# f2838x_cm_cm_nmi_intrupt_regs register map
Vendor: Texas Instruments
Peripheral module from a debugger description file (folder C2000).
Address unit: 16 bits
Registers are 32-bit, read-write, no defined reset value unless marked. A register's access mark holds for its fields unless they carry their own. Offsets are as the file gives them; lines under a group give offsets from that group; [hi:lo] are bit positions; {n}, {i} and the like mark numbered series; 'fields as' and 'values as' point back to an identical list; <NAME> marks a mode.

## CM_NMI_INTRUPT_REGS — CM NMI INTRUPT Registers
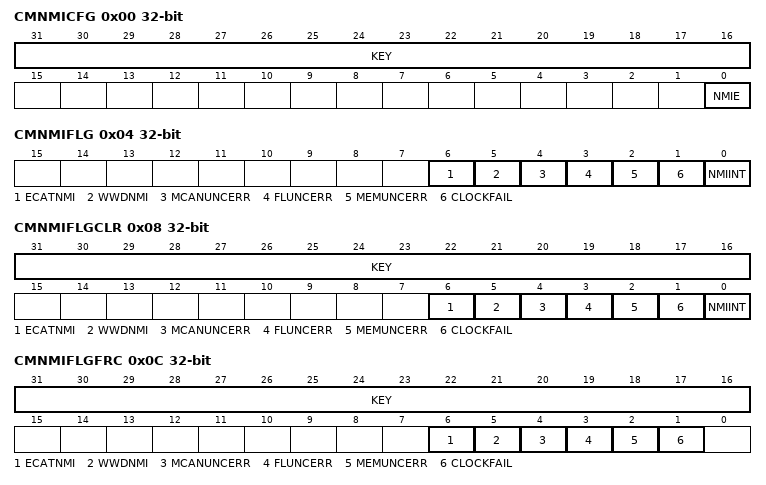
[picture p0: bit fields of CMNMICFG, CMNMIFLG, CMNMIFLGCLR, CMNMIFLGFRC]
0x00 CMNMICFG — CM NMI Configuration Register
  [31:16] KEY — Key protection
  [0] NMIE — Global NMI Enable
0x04 CMNMIFLG ro — CM NMI Flag Register
  [6] ECATNMI — NMI from EtherCAT reset out
  [5] WWDNMI — CM WWD NMI flag
  [4] MCANUNCERR — MCAN Uncorrectable Error NMI Flag
  [3] FLUNCERR — Flash Uncorrectable Error NMI Flag
  [2] MEMUNCERR — RAM, ROM Uncorrectable Error NMI Flag
  [1] CLOCKFAIL — Clock Fail Interrupt Flag
  [0] NMIINT — NMI Interrupt Flag
0x08 CMNMIFLGCLR — CMNMI Flag Clear Register
  [31:16] KEY — Key protection
  [6] ECATNMI — ECATNMI Flag Clear
  [5] WWDNMI — WWDNMI Flag Clear
  [4] MCANUNCERR — MCANUNCERR Flag Clear
  [3] FLUNCERR — FLUNCERR Flag Clear
  [2] MEMUNCERR — MEMUNCERR Flag Clear
  [1] CLOCKFAIL — CLOCKFAIL Flag Clear
  [0] NMIINT — NMIINT Flag Clear
0x0C CMNMIFLGFRC — CMNMI Flag Force Register
  [31:16] KEY — Key protection
  [6] ECATNMI — ECATNMI Flag Force
  [5] WWDNMI — WWDNMI Flag Force
  [4] MCANUNCERR — MCANUNCERR Flag Force
  [3] FLUNCERR — FLUNCERR Flag Force
  [2] MEMUNCERR — MEMUNCERR Flag Force
  [1] CLOCKFAIL — CLOCKFAIL Flag Force
0x10 CMNMIWDCNT ro — CMNMI Watchdog Counter Register
  [15:0] NMIWDCNT — NMI Watchdog Counter
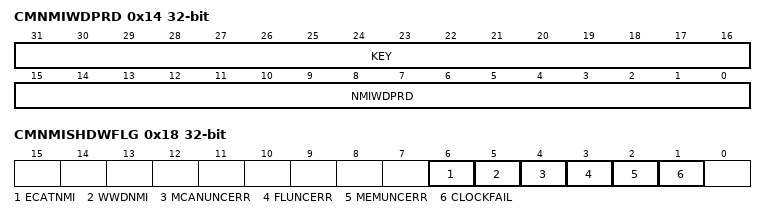
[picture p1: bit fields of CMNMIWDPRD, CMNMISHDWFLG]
0x14 CMNMIWDPRD — CMNMI Watchdog Period Register
  [31:16] KEY — Key protection
  [15:0] NMIWDPRD — NMI Watchdog Period
0x18 CMNMISHDWFLG ro — CMNMI Shadow Flag Register
  [6] ECATNMI — ECATNMI Shadow flag
  [5] WWDNMI — WWDNMI Shadow flag
  [4] MCANUNCERR — MCANUNCERR Shadow flag
  [3] FLUNCERR — FLUNCERR Shadow flag
  [2] MEMUNCERR — MEMUNCERR Shadow flag
  [1] CLOCKFAIL — CLOCKFAIL Shadow flag
